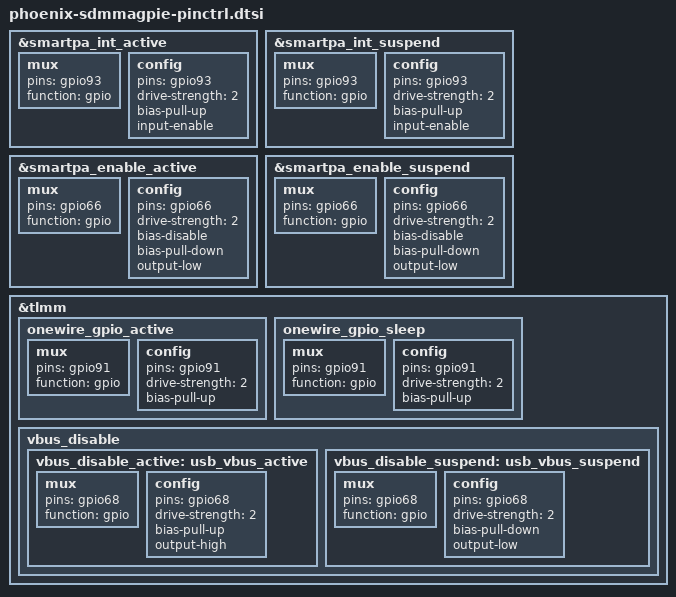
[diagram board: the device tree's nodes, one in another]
/*
 * Copyright (C) 2020 The LineageOS Project
 *
 * this file is for attribution only of phoenix
 * And public attribution of Xiaomi platforms (like G7B and so)
 */

&smartpa_int_active {
    /* active state */
    mux {
        /* GPIO 93 Interrupt */
        pins = "gpio93";
        function = "gpio";
    };

    config {
        pins = "gpio93";
        drive-strength = <2>; /* 2 MA */
        bias-pull-up;
        input-enable;
    };
};

&smartpa_int_suspend {
    /* sleep state */
    mux {
        /* GPIO 93 Interrupt */
        pins = "gpio93";
        function = "gpio";
    };

    config {
        pins = "gpio93";
        drive-strength = <2>; /* 2 MA */
        bias-pull-up;
        input-enable;
    };
};

&smartpa_enable_active {
    /* active state */
    mux {
        /* GPIO 66 rst pin */
        pins = "gpio66";
        function = "gpio";
    };

    config {
        pins = "gpio66";
        drive-strength = <2>;
        bias-disable;
        bias-pull-down;
        output-low;
    };
};

&smartpa_enable_suspend {
    /* sleep state */
    mux {
        /* GPIO 66 rst pin */
        pins = "gpio66";
        function = "gpio";
    };

    config {
        pins = "gpio66";
        drive-strength = <2>;
        bias-disable;
        bias-pull-down;
        output-low;
    };
};

&tlmm {
    onewire_gpio_active: onewire_gpio_active {
        mux {
            pins = "gpio91";
            function = "gpio";
        };

        config {
            pins = "gpio91";
            drive-strength = <2>;
            bias-pull-up; /* No PULL */
        };
    };

    onewire_gpio_sleep: onewire_gpio_sleep {
        mux {
            pins = "gpio91";
            function = "gpio";
        };

        config {
            pins = "gpio91";
            drive-strength = <2>;
            bias-pull-up;
        };
    };

    vbus_disable {
        vbus_disable_active: usb_vbus_active {
            /* active state */
            mux {
                pins = "gpio68";
                function = "gpio";
            };

            config {
                pins = "gpio68";
                drive-strength = <2>; /* 2 MA */
                bias-pull-up;
                output-high;

            };
        };

        vbus_disable_suspend: usb_vbus_suspend {
            mux {
                pins = "gpio68";
                function = "gpio";
            };

            config {
                pins = "gpio68";
                drive-strength = <2>; /* 2 MA */
                bias-pull-down;
                output-low;
            };
        };
    };
};
